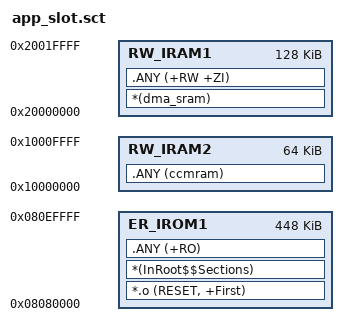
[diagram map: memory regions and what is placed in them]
LR_IROM1 0x08080000 0x00070000  {
  ER_IROM1 0x08080000 0x00070000  {
    *.o (RESET, +First)
    *(InRoot$$Sections)
    .ANY (+RO)
  }

  RW_IRAM1 0x20000000 0x00020000  {
    *(dma_sram)
    .ANY (+RW +ZI)
  }

  RW_IRAM2 0x10000000 0x00010000  {
    .ANY (ccmram)
  }
}
